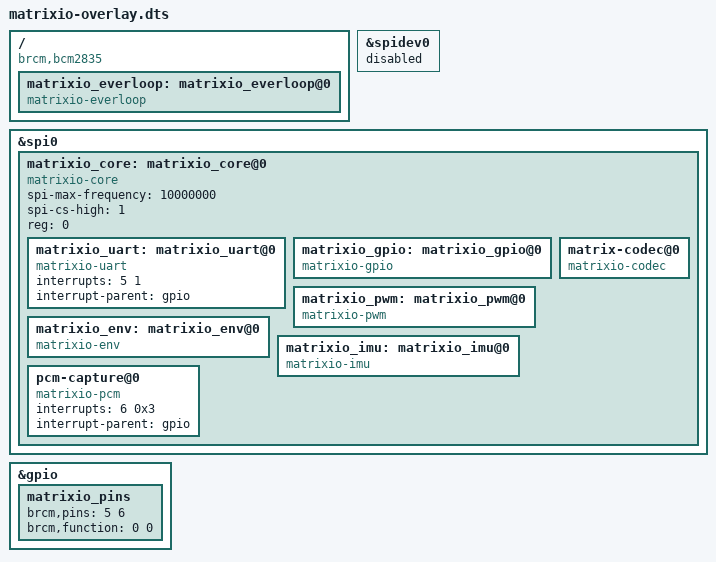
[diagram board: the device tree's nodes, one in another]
/dts-v1/ ;
/plugin/ ;

/ {
	compatible = "brcm,bcm2835", "brcm,bcm2708", "brcm,bcm2709";

	fragment@0 {
		target = <&spidev0>;
		__overlay__ { status = "disabled"; };
	};

	fragment@1 {
		target = <&spi0>;
		__overlay__ {
			#address-cells = <1>;
			#size-cells = <0>;
			status = "okay"; 
			matrixio_core: matrixio_core@0 {
				compatible = "matrixio-core";
				spi-max-frequency = <10000000>;
				spi-cs-high = <1>;
				reg = <0>;
			};
		};
	};


	fragment@2 {
		target = <&gpio>;
		__overlay__ {
			matrixio_pins: matrixio_pins {
				brcm,pins = <5 6>;
				brcm,function = <0 0>;
			};
		};
	};


        fragment@3 {
                target-path = "/";
                __overlay__ {
                        matrixio_everloop: matrixio_everloop@0 {
                                compatible = "matrixio-everloop";

                        };
                };
        };

        fragment@4 {
                target = <&matrixio_core>;
                __overlay__ {
                        matrixio_uart: matrixio_uart@0 {
                                compatible = "matrixio-uart";
				interrupts = <5 1>; /* low-to-high edge triggered */
				interrupt-parent = <&gpio>;
				status = "okay";
                        };
                };
        };

        fragment@5 {
                target = <&matrixio_core>;
                __overlay__ {
                        matrixio_gpio: matrixio_gpio@0 {
                                compatible = "matrixio-gpio";
                                status = "okay";
                        };
                };
        };

        fragment@6 {
                target = <&matrixio_core>;
                __overlay__ {
                        matrixio_pwm: matrixio_pwm@0 {
                                compatible = "matrixio-pwm";
                                status = "okay";
                        };
                };
        };

	fragment@7 {
		target = <&matrixio_core>;
		__overlay__ {
			matrixio_env: matrixio_env@0 {
				compatible = "matrixio-env";
				status = "okay";
			};
		};
	};

	fragment@8 {
		target = <&matrixio_core>;
		__overlay__ {
			matrixio_imu: matrixio_imu@0 {
				compatible = "matrixio-imu";
				status = "okay";
			};
		};
	};

        fragment@9 {
                target = <&matrixio_core>;
                __overlay__ {
                        pcm-capture@0 {
                                compatible = "matrixio-pcm";
                                interrupts = <6 0x3>; /* both edges triggered */
                                interrupt-parent = <&gpio>;
                                status = "okay";
                        };
                };
        };

        fragment@10 {
                target = <&matrixio_core>;
                __overlay__ {
                        matrix-codec@0 {
                                compatible = "matrixio-codec";
                                status = "okay";
                        };
                };
        };
};

